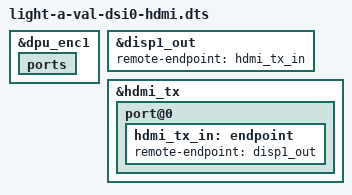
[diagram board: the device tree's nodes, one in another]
/* SPDX-License-Identifier: GPL-2.0 */
/*
 * Copyright (C) 2021 Alibaba Group Holding Limited.
 */

/dts-v1/;

#include "light-a-val-dsi0.dts"

&dpu_enc1 {
        ports {
                /delete-node/ port@0;
        };
};

&disp1_out {
	remote-endpoint = <&hdmi_tx_in>;
};

&hdmi_tx {
	status = "okay";

	port@0 {
		/* input */
		hdmi_tx_in: endpoint {
			remote-endpoint = <&disp1_out>;
		};
	};
};
